AUTOSAR XML (schema 4-2-2)
standard types defined: Boolean, Uint8, Uint16, Uint32
package /DataTypes/ImplementationTypes
  4 x impl type:
    e_UsageMode: compu {0=E_USGMODST_STANDBY, 3=E_USGMODST_COMFORT, 5=E_USGMODST_TOBEDRV, 7=E_USGMODST_DRV, 12=E_USGMODST_NOTUSED}, range raw 0..12, implementation-data-type=Uint8
    e_BatteryMode: compu {0=E_BATMODE_OFF, 1=E_BATMODE_IG, 2=E_BATMODE_ON}, range raw 0..2, implementation-data-type=Uint8
    t_MotorErr: category=STRUCTURE
      element OpenLoad: implementation-data-type=Boolean
      element Short2GND: implementation-data-type=Boolean
      element Short2BAT: implementation-data-type=Boolean
    t_VehicleMode: category=STRUCTURE
      element UsageMode: implementation-data-type=e_UsageMode
      element BatteryMode: implementation-data-type=e_BatteryMode
package /PortInterfaces
  4 x sender receiver interface:
    VehicleConditions
      data FunctionInhibit: type=Boolean
      data MotorErrFlag: type=Boolean
      data SpeedLimited: type=Boolean
    MotorErr
      data LeftMotor: type=t_MotorErr
      data RightMotor: type=t_MotorErr
    VehicleMode
      data Data: type=t_VehicleMode
    GeneralInterface
      data Status: type=Boolean
package /ComponentTypes
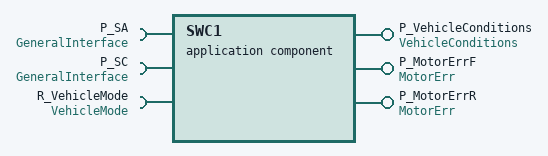
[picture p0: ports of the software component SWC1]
  application sw component type SWC1
    provide port P_VehicleConditions: provided-com-specs=[data-element=FunctionInhibit, data-element=MotorErrFlag, data-element=SpeedLimited], provided-interface=VehicleConditions
    provide port P_MotorErrF: provided-com-specs=[data-element=LeftMotor, data-element=RightMotor], provided-interface=MotorErr
    provide port P_MotorErrR: provided-com-specs=[data-element=LeftMotor, data-element=RightMotor], provided-interface=MotorErr
    require port P_SA: required-interface=GeneralInterface
    require port P_SC: required-interface=GeneralInterface
    require port R_VehicleMode: required-interface=VehicleMode
    behavior SWC1_InternalBehavior
      port-api-options:
        enable-take-address=false, indirect-api=false, port=P_MotorErrF
        enable-take-address=false, indirect-api=false, port=SWC1/P_MotorErrR
        enable-take-address=false, indirect-api=false, port=P_SA
        enable-take-address=false, indirect-api=false, port=SWC1/P_SC
        enable-take-address=false, indirect-api=false, port=SWC1/P_VehicleConditions
        enable-take-address=false, indirect-api=false, port=SWC1/R_VehicleMode
  swc implementation SWC1_Implementation: behavior=SWC1_InternalBehavior
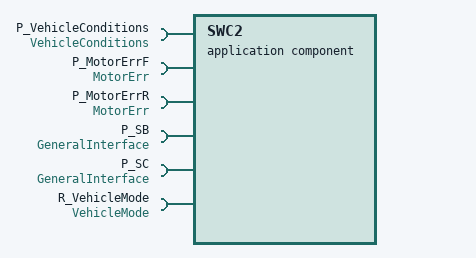
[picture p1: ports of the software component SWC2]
  application sw component type SWC2
    6 x require port:
      P_VehicleConditions: required-interface=VehicleConditions
      P_MotorErrF: required-interface=MotorErr
      P_MotorErrR: required-interface=MotorErr
      P_SB: required-interface=GeneralInterface
      P_SC: required-interface=GeneralInterface
      R_VehicleMode: required-interface=VehicleMode
    behavior SWC2_InternalBehavior
      port-api-options:
        enable-take-address=false, indirect-api=false, port=SWC2/P_MotorErrF
        enable-take-address=false, indirect-api=false, port=P_MotorErrR
        enable-take-address=false, indirect-api=false, port=P_SB
        enable-take-address=false, indirect-api=false, port=SWC2/P_SC
        enable-take-address=false, indirect-api=false, port=P_VehicleConditions
        enable-take-address=false, indirect-api=false, port=SWC2/R_VehicleMode
  swc implementation SWC2_Implementation: behavior=SWC2_InternalBehavior
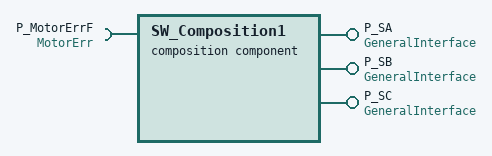
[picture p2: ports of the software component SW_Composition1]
  composition sw component type SW_Composition1
    provide port P_SA: nonqueued-sender-com-spec=data-element=Status, provided-interface=GeneralInterface
    provide port P_SB: nonqueued-sender-com-spec=data-element=Status, provided-interface=GeneralInterface
    provide port P_SC: nonqueued-sender-com-spec=data-element=Status, provided-interface=GeneralInterface
    require port P_MotorErrF: required-interface=MotorErr
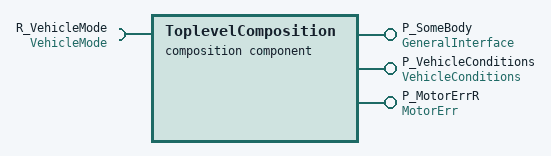
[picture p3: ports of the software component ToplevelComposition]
  composition sw component type ToplevelComposition
    provide port P_SomeBody: nonqueued-sender-com-spec=data-element=Status, provided-interface=GeneralInterface
    provide port P_VehicleConditions: provided-com-specs=[data-element=FunctionInhibit, data-element=MotorErrFlag, data-element=SpeedLimited], provided-interface=VehicleConditions
    provide port P_MotorErrR: provided-com-specs=[data-element=LeftMotor, data-element=RightMotor], provided-interface=MotorErr
    require port R_VehicleMode: required-interface=VehicleMode
    component SWC1: type=SWC1
    component SWC2: type=SWC2
    component SW_Composition1: type=SW_Composition1
    connect SWC1.P_VehicleConditions -> SWC2.P_VehicleConditions
    connect SWC1.P_MotorErrF -> SWC2.P_MotorErrF
    connect SWC1.P_MotorErrF -> SW_Composition1.P_MotorErrF
    connect SWC1.P_MotorErrR -> SWC2.P_MotorErrR
    connect SW_Composition1.P_SA -> SWC1.P_SA
    connect SW_Composition1.P_SB -> SWC2.P_SB
    connect SW_Composition1.P_SC -> SWC2.P_SC
    connect SW_Composition1.P_SC -> SWC1.P_SC
    delegate SWC1.P_VehicleConditions <-> outer port ToplevelComposition/P_VehicleConditions
    delegate SWC1.P_MotorErrR <-> outer port ToplevelComposition/P_MotorErrR
    delegate SWC1.R_VehicleMode <-> outer port ToplevelComposition/R_VehicleMode
    delegate SWC2.R_VehicleMode <-> outer port ToplevelComposition/R_VehicleMode
